LIN_description_file ;
LIN_protocol_version = "2.1" ;
LIN_language_version = "2.1" ;
LIN_speed = 19.200 kbps ;
Nodes {
    Master:BCM,1.0000 ms,0.0000 ms ;
    Slaves:MCM;
}
Signals {
    BCM_PowerKeySt:2,0x0,BCM,MCM;
    BCM_MasLumbarSupFuncButtonSt:1,0x0,BCM,MCM;
    BCM_UpLumbarSupAdjButtonSt:1,0x0,BCM,MCM;
    BCM_DownLumbarSupAdjButtonSt:1,0x0,BCM,MCM;
    BCM_FwdLumbarSupAdjButtonSt:1,0x0,BCM,MCM;
    BCM_RwdLumbarSupAdjButtonSt:1,0x0,BCM,MCM;
    BCM_MasActivated:1,0x0,BCM,MCM;
    BCM_MassageReq:4,0x0,BCM,MCM;
    Reserved0:4,0x0,BCM;
    MCM_MasSt:1,0x0,MCM;
    MCM_MassageSts:4,0x0,MCM;
    MCM_BatVoltAbnormal:2,0x0,MCM;
    Reserved1:1,0x0,MCM,BCM;
    MCM_UpLumbarSupSt:1,0x0,MCM,BCM;
    MCM_DownLumbarSupSt:1,0x0,MCM,BCM;
    MCM_FwdLumbarSupSt:1,0x0,MCM,BCM;
    MCM_RwdLumbarSupSt:1,0x0,MCM,BCM;
    MCM_Resp_Err:1,0x0,MCM,BCM;
}
Frames {
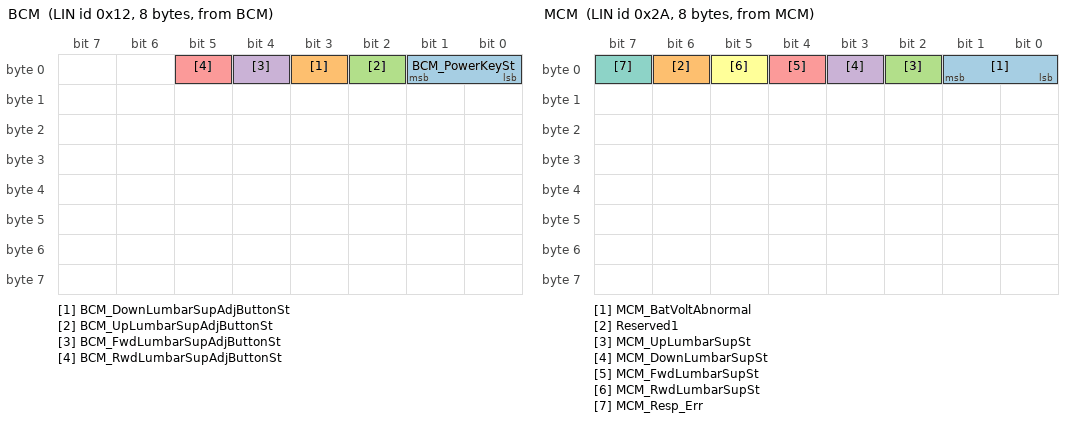
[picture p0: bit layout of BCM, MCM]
    BCM:0x12,BCM,8{
        BCM_PowerKeySt,0;
        BCM_DownLumbarSupAdjButtonSt,3;
        BCM_UpLumbarSupAdjButtonSt,2;
        BCM_FwdLumbarSupAdjButtonSt,4;
        BCM_RwdLumbarSupAdjButtonSt,5;
    }
    MCM:0x2A,MCM,8{
        MCM_BatVoltAbnormal,0;
        Reserved1,6;
        MCM_UpLumbarSupSt,2;
        MCM_DownLumbarSupSt,3;
        MCM_FwdLumbarSupSt,4;
        MCM_RwdLumbarSupSt,5;
        MCM_Resp_Err,7;
    }
}
Node_attributes {
    MCM {
        LIN_protocol = 2.1 ;
        configured_NAD = 0x01 ;
        initial_NAD = 0x00 ;
    }
}
Schedule_tables {
    N60AB {
        BCM delay 100.0000 ms ;
        MCM delay 180.0000 ms ;
    }
}
